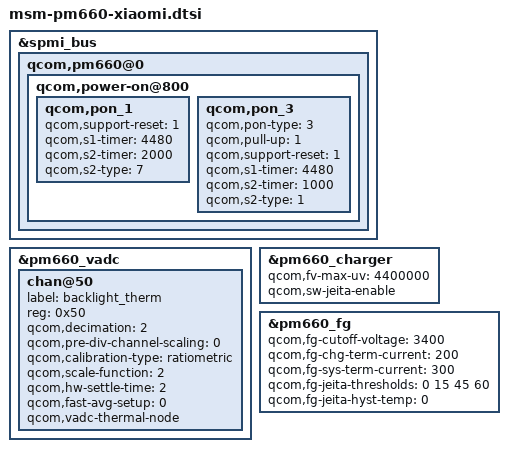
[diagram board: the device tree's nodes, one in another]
&spmi_bus {
	qcom,pm660@0 {
		qcom,power-on@800 {
			qcom,pon_1 {
				qcom,support-reset = <1>;
				qcom,s1-timer = <4480>;
				qcom,s2-timer = <2000>;
				qcom,s2-type = <7>;
			};

			qcom,pon_3 {
				qcom,pon-type = <3>;
				qcom,pull-up = <1>;
				qcom,support-reset = <1>;
				qcom,s1-timer = <4480>;
				qcom,s2-timer = <1000>;
				qcom,s2-type = <1>;
			};
		};
	};
};

&pm660_vadc {
	chan@50 {
		label = "backlight_therm";
		reg = <0x50>;
		qcom,decimation = <2>;
		qcom,pre-div-channel-scaling = <0>;
		qcom,calibration-type = "ratiometric";
		qcom,scale-function = <2>;
		qcom,hw-settle-time = <2>;
		qcom,fast-avg-setup = <0>;
		qcom,vadc-thermal-node;
	};
};

&pm660_charger {
	qcom,fv-max-uv  = <4400000>;
	qcom,sw-jeita-enable;
};

&pm660_fg {
	qcom,fg-cutoff-voltage = <3400>;
	qcom,fg-chg-term-current = <200>;
	qcom,fg-sys-term-current = <300>;
	qcom,fg-jeita-thresholds = <0 15 45 60>;
	qcom,fg-jeita-hyst-temp = <0>;
};
